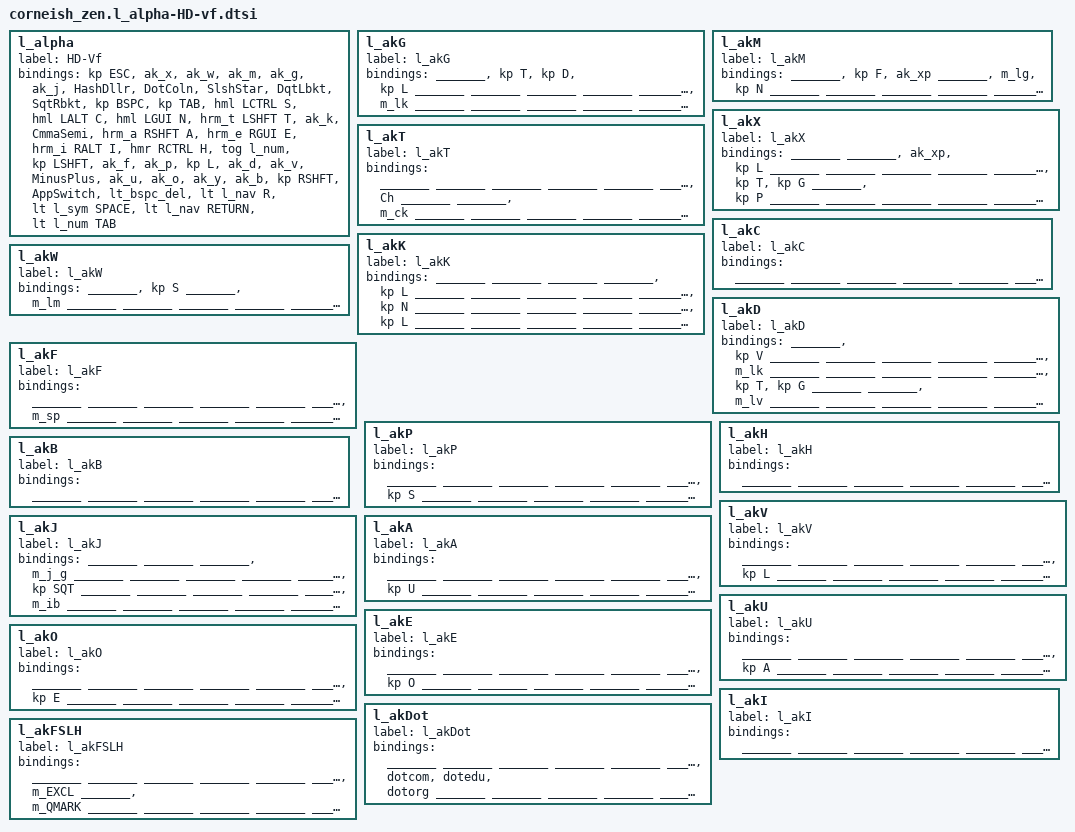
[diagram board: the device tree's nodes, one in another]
#define _______  &trans

/*  Base (alpha) Layer  Hands Down Vibranium-vf
    Building for a 36/42 key board
     ╭─────────────────────╮ ╭──────────────────────╮
ESC  │  X   W   M   G   J  │ │  #$  .:  /*  "[  ']  │ BSP
TAB  │  S   C   N   T   K  | |  ,;   A   E   I   H  │ Tg(Num)
LSFT │  F   P   L   D   V  │ │  -+   U   O   Y   B  │ RSFT
     ╰──────╮  App BSP  R  │ │  SPC RET TAB  ╭──────╯
            ╰──────────────╯ ╰───────────────╯
*/


                    l_alpha {
                        label = "HD-Vf";
                        bindings = <
&kp ESC   &ak_x    &ak_w      &ak_m     &ak_g     &ak_j         &HashDllr  &DotColn    &SlshStar   &DqtLbkt   &SqtRbkt &kp BSPC
&kp TAB &hml LCTRL S &hml LALT C   &hml LGUI N  &hrm_t LSHFT T &ak_k     &CmmaSemi   &hrm_a RSHFT A &hrm_e RGUI E  &hrm_i RALT I  &hmr RCTRL H &tog l_num
&kp LSHFT &ak_f    &ak_p      &kp L     &ak_d     &ak_v         &MinusPlus &ak_u       &ak_o       &ak_y      &ak_b    &kp RSHFT
                   &AppSwitch &lt_bspc_del &lt l_nav R          &lt l_sym SPACE &lt l_nav RETURN  &lt l_num TAB
                        >;
                    };
                    l_akG {
                        label = "l_akG";
                        bindings = <
_______   &kp T     &kp D     &kp L     _______   _______       _______   _______   _______   _______   _______   _______
_______   _______   _______   _______   _______   &m_lk         _______   _______   _______   _______   _______   _______
_______   _______   _______   _______   _______   _______       _______   _______   _______   _______   _______   _______
                              _______   _______   _______       _______   _______   _______
                            >;
                    };
                    l_akM {
                        label = "l_akM";
                        bindings = <
_______   &kp F    &ak_xp    _______   &m_lg     &kp N         _______   _______   _______   _______   _______   _______
_______   _______   _______   _______   _______   _______       _______   _______   _______   _______   _______   _______
_______   _______   _______   _______   _______   _______       _______   _______   _______   _______   _______   _______
                              _______   _______   _______       _______   _______   _______
                        >;
                    };
                    l_akX {
                        label = "l_akX";
                        bindings = <
_______   _______   &ak_xp    &kp L     _______   _______       _______   _______   _______   _______   _______   _______
_______   _______   _______   _______   _______   _______       _______   _______   _______   _______   _______   _______
_______   &kp T     &kp G     _______   &kp P     _______       _______   _______   _______   _______   _______   _______
                              _______   _______   _______       _______   _______   _______
                        >;
                    };
                    l_akT {
                        label = "l_akT";
                        bindings = <
_______   _______   _______   _______   _______   _______       _______   _______   _______   _______   _______   _______
_______   _______   &Ch       _______   _______   &m_ck         _______   _______   _______   _______   _______   _______
_______   _______   _______   _______   _______   _______       _______   _______   _______   _______   _______   _______
                              _______   _______   _______       _______   _______   _______
                            >;
                    };
                    l_akC {
                    label = "l_akC";
                    bindings = <
_______   _______   _______   _______   _______   _______       _______   _______   _______   _______   _______   _______
_______   _______   _______   _______   _______   _______       _______   _______   _______   _______   _______   _______
_______   _______   _______   _______   _______   _______       _______   _______   _______   _______   _______   _______
                              _______   _______   _______       _______   _______   _______
                        >;
                    };
                    l_akK {
                        label = "l_akK";
                        bindings = <
_______   _______   _______   _______   &kp L     _______       _______   _______   _______   _______   _______   _______
_______   _______   _______   _______   &kp N     _______       _______   _______   _______   _______   _______   _______
_______   _______   _______   _______   &kp L     _______       _______   _______   _______   _______   _______   _______
                              _______   _______   _______       _______   _______   _______
                            >;
                    };
                    l_akD {
                        label = "l_akD";
                        bindings = <
_______   &kp V     _______   _______   _______   _______       _______   _______   _______   _______   _______   _______
_______   _______   _______   _______   _______   &m_lk         _______   _______   _______   _______   _______   _______
_______   &kp T     &kp G     _______   _______   &m_lv         _______   _______   _______   _______   _______   _______
                              _______   _______   _______       _______   _______   _______
                            >;
                    };
                    l_akW {
                        label = "l_akW";
                        bindings = <
_______   &kp S     _______   &m_lm     _______   _______       _______   _______   _______   _______   _______   _______
_______   _______   _______   _______   _______   _______       _______   _______   _______   _______   _______   _______
_______   _______   _______   _______   _______   _______       _______   _______   _______   _______   _______   _______
                              _______   _______   _______       _______   _______   _______
                        >;
                    };
                    l_akF {
                        label = "l_akF";
                        bindings = <
_______   _______   _______   _______   _______   _______       _______   _______   _______   _______   _______   _______
_______   _______   _______   _______   _______   _______       _______   _______   _______   _______   _______   _______
_______   _______   &m_sp     _______   _______   _______       _______   _______   _______   _______   _______   _______
                              _______   _______   _______       _______   _______   _______
                            >;
                    };
                    l_akP {
                        label = "l_akP";
                        bindings = <
_______   _______   _______   _______   _______   _______       _______   _______   _______   _______   _______   _______
_______   _______   _______   _______   _______   _______       _______   _______   _______   _______   _______   _______
_______   &kp S     _______   _______   _______   _______       _______   _______   _______   _______   _______   _______
                              _______   _______   _______       _______   _______   _______
                            >;
                    };
                    l_akH {
                        label = "l_akH";
                        bindings = <
_______   _______   _______   _______   _______   _______       _______   _______   _______   _______   _______   _______
_______   _______   _______   _______   _______   _______       _______   _______   _______   _______   _______   _______
_______   _______   _______   _______   _______   _______       _______   _______   _______   _______   _______   _______
                              _______   _______   _______       _______   _______   _______
                            >;
                    };
                    l_akB {
                        label = "l_akB";
                        bindings = <
_______   _______   _______   _______   _______   _______       _______   _______   _______   _______   _______   _______
_______   _______   _______   _______   _______   _______       _______   _______   _______   _______   _______   _______
_______   _______   _______   _______   _______   _______       _______   _______   _______   _______   _______   _______
                              _______   _______   _______       _______   _______   _______
                            >;
                    };
                    l_akV {
                        label = "l_akV";
                        bindings = <
_______   _______   _______   _______   _______   _______       _______   _______   _______   _______   _______   _______
_______   _______   _______   _______   _______   _______       _______   _______   _______   _______   _______   _______
_______   _______   _______   _______   &kp L     _______       _______   _______   _______   _______   _______   _______
                              _______   _______   _______       _______   _______   _______
                        >;
                    };
                    l_akJ { // using l_akJ for Y as well
                        label = "l_akJ";
                        bindings = <
_______   _______   _______   &m_j_g    _______   _______       _______   _______   _______   _______   _______   _______
_______   _______   _______   _______   _______   _______       _______   _______   _______   _______   &kp SQT   _______
_______   _______   _______   _______   _______   _______       _______   _______   _______   _______   &m_ib     _______
                              _______   _______   _______       _______   _______   _______
                        >;
                    };


                    l_akA {
                        label = "l_akA";
                        bindings = <
_______   _______   _______   _______   _______   _______       _______   _______   _______   _______   _______   _______
_______   _______   _______   _______   _______   _______       _______   _______   &kp U     _______   _______   _______
_______   _______   _______   _______   _______   _______       _______   _______   _______   _______   _______   _______
                              _______   _______   _______       _______   _______   _______
                        >;
                    };
                    l_akU {
                        label = "l_akU";
                        bindings = <
_______   _______   _______   _______   _______   _______       _______   _______   _______   _______   _______   _______
_______   _______   _______   _______   _______   _______       _______   _______   _______   _______   &kp A     _______
_______   _______   _______   _______   _______   _______       _______   _______   _______   _______   _______   _______
                              _______   _______   _______       _______   _______   _______
                            >;
                    };
                   l_akE {
                        label = "l_akE";
                        bindings = <
_______   _______   _______   _______   _______   _______       _______   _______   _______   _______   _______   _______
_______   _______   _______   _______   _______   _______       _______   _______   _______   _______   &kp O     _______
_______   _______   _______   _______   _______   _______       _______   _______   _______   _______   _______   _______
                              _______   _______   _______       _______   _______   _______
                            >;
                   };
                   l_akO {
                        label = "l_akO";
                        bindings = <
_______   _______   _______   _______   _______   _______       _______   _______   _______   _______   _______   _______
_______   _______   _______   _______   _______   _______       _______   _______   _______   _______   &kp E     _______
_______   _______   _______   _______   _______   _______       _______   _______   _______   _______   _______   _______
                              _______   _______   _______       _______   _______   _______
                            >;
                   };
                   l_akI {
                        label = "l_akI";
                            bindings = <
_______   _______   _______   _______   _______   _______       _______   _______   _______   _______   _______   _______
_______   _______   _______   _______   _______   _______       _______   _______   _______   _______   _______   _______
_______   _______   _______   _______   _______   _______       _______   _______   _______   _______   _______   _______
                              _______   _______   _______       _______   _______   _______
                        >;
                   };

                   l_akDot {
                        label = "l_akDot";
                        bindings = <
_______   _______   _______   _______   _______   _______       _______   _______   &dotcom   &dotedu   &dotorg   _______
_______   _______   _______   _______   _______   _______       _______   _______   _______   _______   _______   _______
_______   _______   _______   _______   _______   _______       _______   _______   _______   _______   _______   _______
                              _______   _______   _______       _______   _______   _______
                            >;
                   };
                l_akFSLH {
                        label = "l_akFSLH";
                        bindings = <

_______   _______   _______   _______   _______   _______       _______   &m_EXCL   _______  &m_QMARK   _______   _______
_______   _______   _______   _______   _______   _______       _______   _______   _______   _______   _______   _______
_______   _______   _______   _______   _______   _______       _______   _______   _______   _______   _______   _______
                              _______   _______   _______       _______   _______   _______
                        >;
                };
